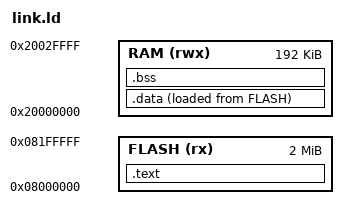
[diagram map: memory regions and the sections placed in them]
/* Minimal STM32F429 layout for emulator self-tests. */
MEMORY
{
  FLASH (rx)  : ORIGIN = 0x08000000, LENGTH = 2048K
  RAM   (rwx) : ORIGIN = 0x20000000, LENGTH = 192K
}
ENTRY(Reset_Handler)
SECTIONS
{
  .text : {
    KEEP(*(.vectors))
    *(.text*)
    *(.rodata*)
    . = ALIGN(4);
  } > FLASH
  _sidata = LOADADDR(.data);
  .data : {
    _sdata = .;
    *(.data*)
    . = ALIGN(4);
    _edata = .;
  } > RAM AT > FLASH
  .bss (NOLOAD) : {
    _sbss = .;
    *(.bss*) *(COMMON)
    . = ALIGN(4);
    _ebss = .;
  } > RAM
  _estack = ORIGIN(RAM) + LENGTH(RAM);
  /DISCARD/ : { *(.ARM.exidx*) *(.comment) }
}
